# RX64M_EDMAC_Pilot register map
File version: 1.0
RX64M_EDMAC_Pilot peripheral registers generated from iodefine.h (pilot).
Registers are 32-bit, read-write, reset 0x0 unless marked. A register's access mark holds for its fields unless they carry their own. Offsets are from the block's base; lines under a group give offsets from that group; [hi:lo] are bit positions; {n}, {i} and the like mark numbered series; 'fields as' and 'values as' point back to an identical list; <NAME> marks a mode.

## Memory map
0x000C0000 EDMAC0 size 0xDC
0x000C0200 EDMAC1 size 0xDC

## EDMAC0
Base 0x000C0000
Same registers: EDMAC1 0x000C0200
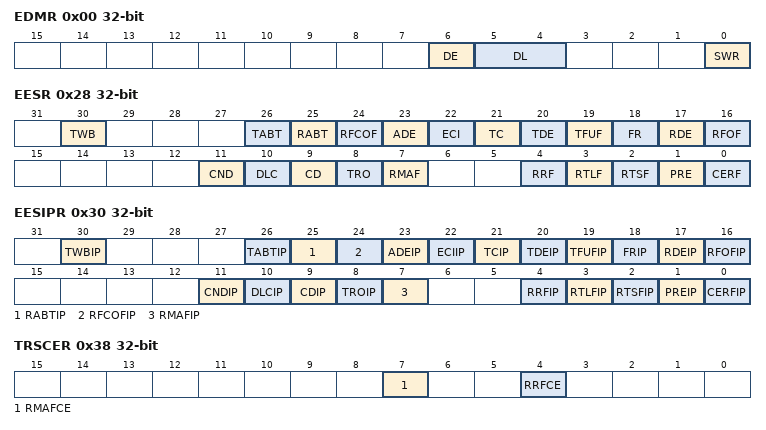
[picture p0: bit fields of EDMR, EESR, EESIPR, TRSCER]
0x00 EDMR
  [6] DE, [5:4] DL, [0] SWR
0x08 EDTRR
  [0] TR
0x10 EDRRR
  [0] RR
0x18 TDLAR
0x20 RDLAR
0x28 EESR
  [30] TWB, [26] TABT, [25] RABT, [24] RFCOF, [23] ADE, [22] ECI, [21] TC, [20] TDE, [19] TFUF, [18] FR, [17] RDE, [16] RFOF, [11] CND, [10] DLC, [9] CD, [8] TRO, [7] RMAF, [4] RRF, [3] RTLF, [2] RTSF, [1] PRE, [0] CERF
0x30 EESIPR
  [30] TWBIP, [26] TABTIP, [25] RABTIP, [24] RFCOFIP, [23] ADEIP, [22] ECIIP, [21] TCIP, [20] TDEIP, [19] TFUFIP, [18] FRIP, [17] RDEIP, [16] RFOFIP, [11] CNDIP, [10] DLCIP, [9] CDIP, [8] TROIP, [7] RMAFIP, [4] RRFIP, [3] RTLFIP, [2] RTSFIP, [1] PREIP, [0] CERFIP
0x38 TRSCER
  [7] RMAFCE, [4] RRFCE
0x40 RMFCR
  [15:0] MFC
0x48 TFTR
  [10:0] TFT
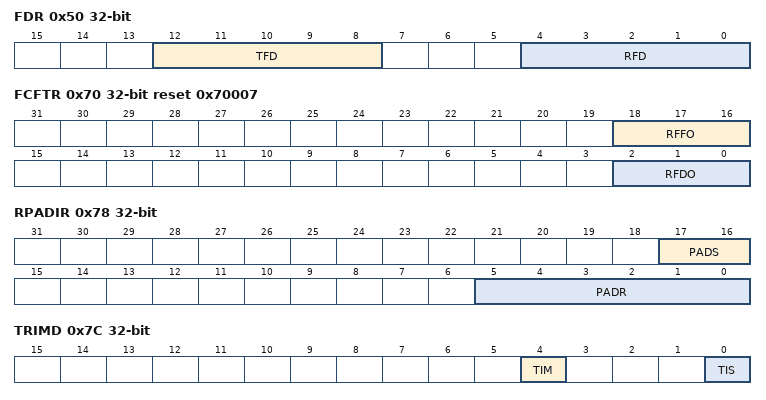
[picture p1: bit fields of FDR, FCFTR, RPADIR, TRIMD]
0x50 FDR
  [12:8] TFD, [4:0] RFD
0x58 RMCR
  [0] RNR
0x64 TFUCR
  [15:0] UNDER
0x68 RFOCR
  [15:0] OVER
0x6C IOSR
  [0] ELB
0x70 FCFTR reset 0x70007
  [18:16] RFFO, [2:0] RFDO
0x78 RPADIR
  [17:16] PADS, [5:0] PADR
0x7C TRIMD
  [4] TIM, [0] TIS
0xC8 RBWAR ro
0xCC RDFAR ro
0xD4 TBRAR ro
0xD8 TDFAR ro
